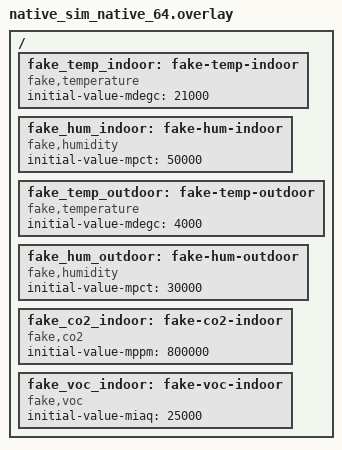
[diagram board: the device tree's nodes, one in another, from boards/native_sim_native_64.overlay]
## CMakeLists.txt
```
# SPDX-License-Identifier: Apache-2.0

cmake_minimum_required(VERSION 3.20.0)

find_package(Zephyr REQUIRED HINTS $ENV{ZEPHYR_BASE})
project(integration VERSION 0.1.0)

target_sources(app PRIVATE src/main.c)

# Expose the shared include/ directory so weather_messages.h is reachable.
target_include_directories(app PRIVATE ${CMAKE_SOURCE_DIR}/../../include)
```

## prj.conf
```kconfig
# Gateway application configuration
# All features are enabled here; logic lives in libraries.

CONFIG_ZBUS=y
CONFIG_ZBUS_CHANNEL_NAME=y
CONFIG_ZBUS_OBSERVER_NAME=y
CONFIG_ZBUS_RUNTIME_OBSERVERS=y

CONFIG_SHELL=y
CONFIG_SHELL_BACKEND_SERIAL=y

CONFIG_LOG=y
#debug for modules
CONFIG_HTTP_DASHBOARD_LOG_LEVEL_DBG=y
CONFIG_MQTT_PUBLISHER_LOG_LEVEL_DBG=y

CONFIG_SENSOR_EVENT=y
CONFIG_SENSOR_EVENT_LOG=y
CONFIG_SENSOR_TRIGGER=y
CONFIG_SENSOR_REGISTRY=y
CONFIG_SENSOR_REGISTRY_USER_META=y
CONFIG_SETTINGS=y
CONFIG_SETTINGS_RUNTIME=y
CONFIG_SENSOR_REGISTRY_SETTINGS=y
CONFIG_CONFIG_CMD=y
CONFIG_FAKE_SENSORS=y
CONFIG_FAKE_SENSORS_SHELL=y
CONFIG_FAKE_SENSORS_AUTO_PUBLISH_MS=5000

# Networking via Native Offloaded Sockets (uses host network stack, no TAP)
# Pattern taken from samples/net/sockets/sntp_client/overlay-nsos.conf
CONFIG_NETWORKING=y
CONFIG_NET_IPV4=y
CONFIG_NET_IPV6=y
CONFIG_NET_UDP=y
CONFIG_NET_SOCKETS=y
CONFIG_ETH_NATIVE_TAP=n
CONFIG_NET_DRIVERS=y
CONFIG_NET_SOCKETS_OFFLOAD=y
CONFIG_NET_NATIVE_OFFLOADED_SOCKETS=y
CONFIG_HEAP_MEM_POOL_SIZE=32768
CONFIG_SYSTEM_WORKQUEUE_STACK_SIZE=4096
# ZVFS poll slots: eventfd(1) + listen(1) + max_clients(3) + margin(3) = 8
# Default of 3 is too small; exhaustion leaves stale epoll entries that cause
# EPOLL_CTL_ADD EEXIST on FD reuse → nsi_print_error_and_exit → DUT exits.
CONFIG_ZVFS_POLL_MAX=8
# One context per open socket; HTTP + MQTT + SNTP + remote scan exhaust the
# default of 6.
CONFIG_NET_MAX_CONTEXTS=16
CONFIG_NET_IPV6_DAD=n

# Network debug shell commands
CONFIG_NET_SHELL=y
CONFIG_NET_STATISTICS=y
CONFIG_NET_STATISTICS_USER_API=y
CONFIG_NET_IPV4_AUTO=n
CONFIG_DNS_RESOLVER=y
CONFIG_DNS_RESOLVER_ADDITIONAL_BUF_CTR=2

# Wall-clock time: net_config SNTP client (same symbols as apps/gateway).
CONFIG_SNTP=y
CONFIG_NET_CONFIG_SETTINGS=y
CONFIG_NET_CONFIG_CLOCK_SNTP_INIT=y
# Use a numeric IP so SNTP skips DNS resolution, avoiding fd exhaustion when
# the HTTP server + MQTT are concurrently holding sockets on native_sim.
CONFIG_NET_CONFIG_SNTP_INIT_SERVER="216.239.35.0"
CONFIG_NET_CONFIG_SNTP_INIT_SERVER_RUNTIME=y
CONFIG_NET_CONFIG_SNTP_INIT_RESYNC=y
# Retry a failed sync after a minute, not after the full resync interval.
CONFIG_NET_CONFIG_SNTP_INIT_RESYNC_ON_FAILURE_INTERVAL=60
CONFIG_NET_SOCKETS_SERVICE=y
# The async SNTP reply (clock set + logging) runs on the socket-service thread.
CONFIG_NET_SOCKETS_SERVICE_STACK_SIZE=2048
# Short timeout: the devcontainer may not reach external NTP servers.
CONFIG_NET_CONFIG_SNTP_INIT_TIMEOUT=1000

# Clock display (HH:MM UTC every minute)
CONFIG_CLOCK_DISPLAY=y

# LVGL graphical display (320x240 SDL window)


# Location registry (auto-selected by HTTP_DASHBOARD, but also enable shell + persistence)
CONFIG_LOCATION_REGISTRY_SETTINGS=y
CONFIG_LOCATION_REGISTRY_SHELL=y

# HTTP dashboard
# Remote sensor transport abstraction + fake stub for native_sim testing
CONFIG_REMOTE_SENSOR=y
CONFIG_REMOTE_SENSOR_SHELL=y
CONFIG_FAKE_REMOTE_SENSOR=y

# FIFO transport: receives sensor-node protobuf readings on /tmp/ws-node-0
CONFIG_PIPE_TRANSPORT=y

# MQTT publisher
# Startup delay gives HTTP server time to finish epoll setup before MQTT opens
# a TCP socket (both share the NSOS epoll fd). 100 ms is sufficient on native_sim.
CONFIG_MQTT_PUBLISHER_STARTUP_DELAY_MS=100
CONFIG_MQTT_PUBLISHER_SHELL=y
CONFIG_MQTT_LIB=y
CONFIG_MQTT_PUBLISHER=y
CONFIG_MQTT_PUBLISHER_GATEWAY_NAME="weather"
CONFIG_MQTT_PUBLISHER_BROKER_HOST="localhost"
CONFIG_MQTT_PUBLISHER_BROKER_PORT=1883

CONFIG_HTTP_DASHBOARD=y
CONFIG_HTTP_DASHBOARD_PORT=8080
CONFIG_NET_TCP=y
CONFIG_HTTP_SERVER=y

CONFIG_HTTP_PARSER=y
CONFIG_HTTP_PARSER_URL=y
CONFIG_HTTP_SERVER_NUM_SERVICES=1
CONFIG_HTTP_SERVER_MAX_CLIENTS=3
CONFIG_HTTP_SERVER_CLIENT_BUFFER_SIZE=512
CONFIG_HTTP_SERVER_MAX_URL_LENGTH=128

# HTTP dashboard session + API token auth
CONFIG_HTTP_DASHBOARD_AUTH=y
CONFIG_HTTP_DASHBOARD_AUTH_SHELL=y
CONFIG_HTTP_DASHBOARD_AUTH_DEFAULT_USER="admin"
CONFIG_HTTP_DASHBOARD_AUTH_DEFAULT_PASS="admin"
CONFIG_HTTP_DASHBOARD_SESSION_COUNT=4
# HTTP_SERVER_CAPTURE_HEADERS auto-selected by HTTP_DASHBOARD_AUTH.
# Capture both Cookie (session) and Authorization (API token) headers → count=2.
CONFIG_HTTP_SERVER_CAPTURE_HEADER_COUNT=2
CONFIG_HTTP_SERVER_CAPTURE_HEADER_BUFFER_SIZE=128
CONFIG_HTTP_SERVER_MAX_HEADER_LEN=64

# Increase HTTP server logging to debug level to observe client slot lifecycle
CONFIG_NET_HTTP_SERVER_LOG_LEVEL_DBG=y
# Reduce inactivity timeout so lingering keep-alive slots are freed within 2 s
# (default is 10 s, which exceeds the inter-POST sleep in tests)
CONFIG_HTTP_SERVER_CLIENT_INACTIVITY_TIMEOUT=2

CONFIG_STACK_CANARIES=y
CONFIG_STACK_SENTINEL=y
```

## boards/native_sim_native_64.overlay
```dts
/*
 * SPDX-License-Identifier: Apache-2.0
 *
 * Integration test DT overlay for native_sim/native/64.
 *
 * Same fake sensor set as apps/gateway — no SDL display since LVGL is
 * disabled for integration testing (the shell must run on stdin/stdout).
 */

/ {
	fake_temp_indoor: fake-temp-indoor {
		compatible = "fake,temperature";
		initial-value-mdegc = <21000>;
		status = "okay";
	};

	fake_hum_indoor: fake-hum-indoor {
		compatible = "fake,humidity";
		initial-value-mpct = <50000>;
		status = "okay";
	};

	fake_temp_outdoor: fake-temp-outdoor {
		compatible = "fake,temperature";
		initial-value-mdegc = <4000>;
		status = "okay";
	};

	fake_hum_outdoor: fake-hum-outdoor {
		compatible = "fake,humidity";
		initial-value-mpct = <30000>;
		status = "okay";
	};

	fake_co2_indoor: fake-co2-indoor {
		compatible = "fake,co2";
		initial-value-mppm = <800000>;
		status = "okay";
	};

	fake_voc_indoor: fake-voc-indoor {
		compatible = "fake,voc";
		initial-value-miaq = <25000>;
		status = "okay";
	};
};
```

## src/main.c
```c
/* SPDX-License-Identifier: Apache-2.0 */
/**
 * @file main.c (integration test app)
 * @brief Integration test entry point — full gateway stack, no LVGL display.
 *
 * Mirrors apps/gateway but disables the LVGL display so the process does not
 * block on SDL and the pytest-twister-harness can interact via stdin/stdout.
 *
 * All subsystem logic (HTTP dashboard, MQTT, fake sensors, etc.) initialises
 * via SYS_INIT callbacks driven by prj.conf Kconfig selections.
 */

#include <zephyr/kernel.h>
#include <zephyr/logging/log.h>

LOG_MODULE_REGISTER(integration, LOG_LEVEL_INF);

int main(void)
{
	/*
	 * All SYS_INIT callbacks (HTTP server, MQTT publisher, fake sensors, …)
	 * have completed by the time main() runs.  Emit a well-known sentinel
	 * that the pytest conftest waits for before starting any test:
	 *
	 *   [00:00:00.xxx] <inf> integration: device: ready
	 *
	 * grep pattern used by the device_ready fixture:
	 *   r"integration:.*device:.*ready"
	 */
	k_sleep(K_SECONDS(1));
	LOG_INF("device: ready");
	return 0;
}
```
